# STM32H755xx_CM4 register map
File version: 1.0
Registers are 32-bit, read-write, reset 0x0 unless marked. A register's access mark holds for its fields unless they carry their own. Offsets are from the block's base; [hi:lo] are bit positions.

## QUADSPI — QUAD Serial Peripheral Interface
Base 0x52005000
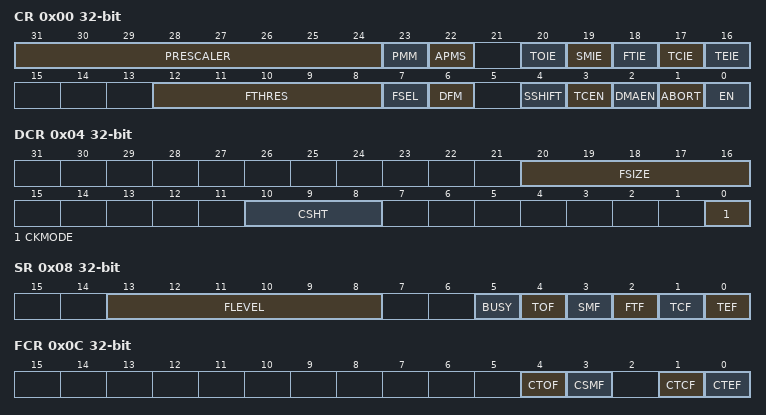
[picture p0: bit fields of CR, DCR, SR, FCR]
0x00 CR — QUADSPI Control register
  [31:24] PRESCALER — PRESCALER[7:0] Clock prescaler
  [23] PMM — Polling Match Mode
  [22] APMS — Bit 1
  [20] TOIE — TimeOut Interrupt Enable
  [19] SMIE — Status Match Interrupt Enable
  [18] FTIE — FIFO Threshold Interrupt Enable
  [17] TCIE — Transfer Complete Interrupt Enable
  [16] TEIE — Transfer Error Interrupt Enable
  [12:8] FTHRES — FTHRES[4:0] FIFO Level
  [7] FSEL — Flash Select
  [6] DFM — Dual Flash Mode
  [4] SSHIFT — SSHIFT Sample Shift
  [3] TCEN — Timeout Counter Enable
  [2] DMAEN — Reserved: needed for softawre compatibility (DMA Enable)
  [1] ABORT — Abort request
  [0] EN — Enable
0x04 DCR — QUADSPI Device Configuration register
  [20:16] FSIZE — FSIZE[4:0]: Flash Size
  [10:8] CSHT — CSHT[2:0]: ChipSelect High Time
  [0] CKMODE — Mode 0 / Mode 3
0x08 SR — QUADSPI Status register
  [13:8] FLEVEL — FIFO Threshlod Flag
  [5] BUSY
  [4] TOF — Timeout Flag
  [3] SMF — Status Match Flag
  [2] FTF — FIFO Threshlod Flag
  [1] TCF — Transfer Complete Flag
  [0] TEF — Transfer Error Flag
0x0C FCR — QUADSPI Flag Clear register
  [4] CTOF — Clear Timeout Flag
  [3] CSMF — Clear Status Match Flag
  [1] CTCF — Clear Transfer Complete Flag
  [0] CTEF — Clear Transfer Error Flag
0x10 DLR — QUADSPI Data Length register
  [31:0] DL — DL[31:0]: Data Length
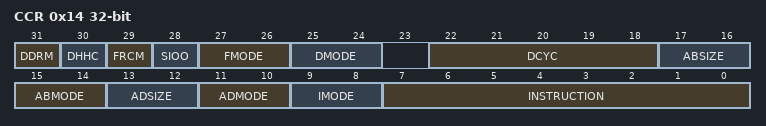
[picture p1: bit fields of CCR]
0x14 CCR — QUADSPI Communication Configuration register
  [31] DDRM — DDRM: Double Data Rate Mode
  [30] DHHC — DHHC: DDR hold half cycle
  [29] FRCM — FRCM: Free-running clock mode
  [28] SIOO — SIOO: Send Instruction Only Once Mode
  [27:26] FMODE — FMODE[1:0]: Functional Mode
  [25:24] DMODE — DMODE[1:0]: Data Mode
  [22:18] DCYC — DCYC[4:0]: Dummy Cycles
  [17:16] ABSIZE — ABSIZE[1:0]: Instruction Mode
  [15:14] ABMODE — ABMODE[1:0]: Alternate Bytes Mode
  [13:12] ADSIZE — ADSIZE[1:0]: Address Size
  [11:10] ADMODE — ADMODE[1:0]: Address Mode
  [9:8] IMODE — IMODE[1:0]: Instruction Mode
  [7:0] INSTRUCTION — INSTRUCTION[7:0]: Instruction
0x18 AR — QUADSPI Address register
  [31:0] ADDRESS — ADDRESS[31:0]: Address
0x1C ABR — QUADSPI Alternate Bytes register
  [31:0] ALTERNATE — ALTERNATE[31:0]: Alternate Bytes
0x20 DR — QUADSPI Data register
  [31:0] DATA — DATA[31:0]: Data
0x24 PSMKR — QUADSPI Polling Status Mask register
  [31:0] MASK — MASK[31:0]: Status Mask
0x28 PSMAR — QUADSPI Polling Status Match register
  [31:0] MATCH — MATCH[31:0]: Status Match
0x2C PIR — QUADSPI Polling Interval register
  [15:0] INTERVAL — INTERVAL[15:0]: Polling Interval
0x30 LPTR — QUADSPI Low Power Timeout register
  [15:0] TIMEOUT — TIMEOUT[15:0]: Timeout period

## COMP12 — Comparator
Base 0x58003800
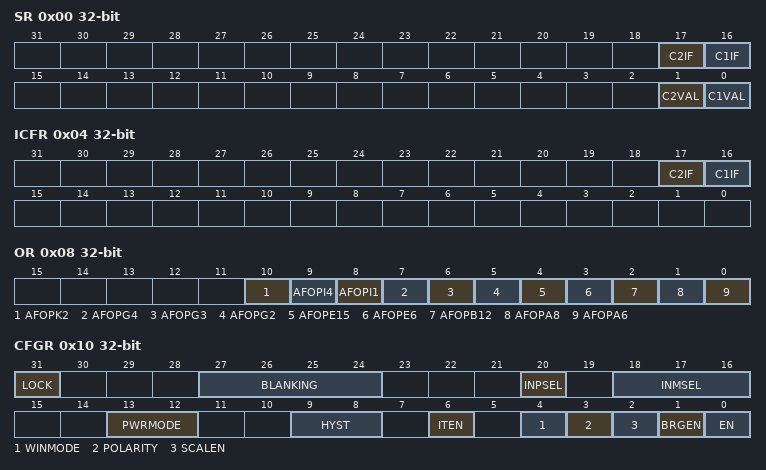
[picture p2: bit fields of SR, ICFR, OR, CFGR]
0x00 SR — Comparator status register
  [17] C2IF, [16] C1IF, [1] C2VAL, [0] C1VAL
0x04 ICFR — Comparator interrupt clear flag register
  [17] C2IF, [16] C1IF
0x08 OR — Comparator option register
  [10] AFOPK2, [9] AFOPI4, [8] AFOPI1, [7] AFOPG4, [6] AFOPG3, [5] AFOPG2, [4] AFOPE15, [3] AFOPE6, [2] AFOPB12, [1] AFOPA8, [0] AFOPA6
0x10 CFGR — COMP control and status register, used for bits common to several COMP instances
  [31] LOCK — COMPx Lock Bit
  [27:24] BLANKING — COMPx blanking source selection bits
    0=NONE (Comparator output without blanking); 1=TIM1_OC5 (Comparator output blanking source TIM1 OC5 (common to all COMP instances: COMP1, COMP2)); 2=TIM2_OC3 (Comparator output blanking source TIM2 OC3 (common to all COMP instances: COMP1, COMP2)); 3=TIM3_OC3 (Comparator output blanking source TIM3 OC3 (common to all COMP instances: COMP1, COMP2)); 4=TIM3_OC4 (Comparator output blanking source TIM3 OC4 (common to all COMP instances: COMP1, COMP2)); 5=TIM8_OC5 (Comparator output blanking source TIM8 OC5 (common to all COMP instances: COMP1, COMP2)); 6=TIM15_OC1 (Comparator output blanking source TIM15 OC1 (common to all COMP instances: COMP1, COMP2))
  [20] INPSEL — COMPx input plus selection bit
  [18:16] INMSEL — COMPx input minus selection bit
  [13:12] PWRMODE — COMPx Power Mode of the comparator
    0=HIGHSPEED (COMP power mode to high speed); 1=MEDIUMSPEED (COMP power mode to medium speed); 3=ULTRALOWPOWER (COMP power mode to ultra-low power)
  [9:8] HYST — COMPx hysteresis selection bits
    0=NONE (No hysteresis); 1=LOW (Hysteresis level low); 2=MEDIUM (Hysteresis level medium); 3=HIGH (Hysteresis level high)
  [6] ITEN — COMPx interrupt enable
  [4] WINMODE — COMPx Windows mode selection bit
    0=DISABLE (Window mode disable: Comparators 1 and 2 are independent); 1=COMP1_INPUT_PLUS_COMMON (Window mode enable: Comparators instances pair COMP1 and COMP2 have their input plus connected together. The common input is COMP1 input plus (COMP2 input plus is no more accessible).)
  [3] POLARITY — COMPx polarity selection bit
    0=NONINVERTED (COMP output polarity is not inverted: comparator output is high when the plus (non-inverting) input is at a higher voltage than the minus (inverting) input); 1=INVERTED (COMP output polarity is inverted: comparator output is low when the plus (non-inverting) input is at a lower voltage than the minus (inverting) input)
  [2] SCALEN — COMPx Voltage scaler enable bit
  [1] BRGEN — COMPx Scaler bridge enable
  [0] EN — COMPx enable bit
